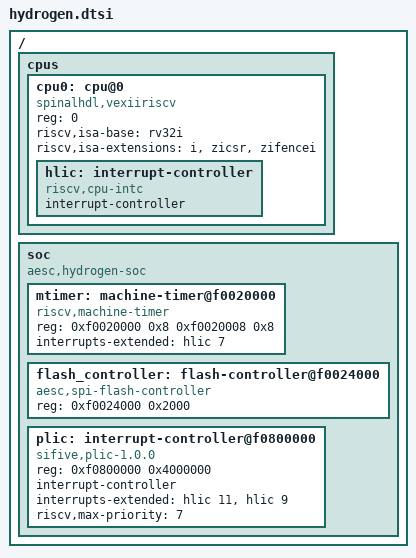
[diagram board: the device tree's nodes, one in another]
/*
 * SPDX-FileCopyrightText: 2026 Aesc Silicon
 *
 * SPDX-License-Identifier: Apache-2.0
 */

#include <zephyr/dt-bindings/gpio/gpio.h>
#include <freq.h>
#include <mem.h>

/ {
	#address-cells = <1>;
	#size-cells = <1>;

	cpus {
		#address-cells = <1>;
		#size-cells = <0>;

		cpu0: cpu@0 {
			compatible = "spinalhdl,vexiiriscv", "riscv";
			reg = <0>;
			device_type = "cpu";
			riscv,isa-base = "rv32i";
			riscv,isa-extensions = "i", "zicsr", "zifencei";
			status = "okay";

			hlic: interrupt-controller {
				compatible = "riscv,cpu-intc";
				#address-cells = <0>;
				#interrupt-cells = <1>;
				interrupt-controller;
			};
		};
	};

	soc {
		compatible = "aesc,hydrogen-soc", "simple-bus";
		ranges;
		#address-cells = <1>;
		#size-cells = <1>;

		mtimer: machine-timer@f0020000 {
			compatible = "riscv,machine-timer";
			reg = <0xf0020000 0x8 0xf0020008 0x8>;
			reg-names = "mtime", "mtimecmp";
			interrupts-extended = <&hlic 7>;
			status = "okay";
		};

		flash_controller: flash-controller@f0024000 {
			compatible = "aesc,spi-flash-controller";
			reg = <0xf0024000 0x2000>;
			ranges;
			#address-cells = <1>;
			#size-cells = <1>;
			status = "okay";
		};

		/* RISC-V Platform-level interrupt controller */
		plic: interrupt-controller@f0800000 {
			compatible = "sifive,plic-1.0.0";
			reg = <0xf0800000 0x4000000>;
			#address-cells = <0>;
			#interrupt-cells = <2>;
			interrupt-controller;
			interrupts-extended = <&hlic 11 &hlic 9>;
			riscv,max-priority = <7>;
			status = "okay";
		};
	};
};
